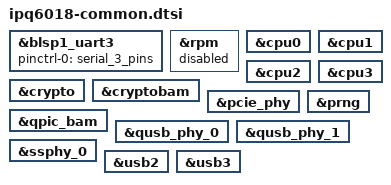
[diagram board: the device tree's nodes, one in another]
// SPDX-License-Identifier: GPL-2.0-or-later OR MIT

&blsp1_uart3 {
	status = "okay";
	pinctrl-0 = <&serial_3_pins>;
	pinctrl-names = "default";
};

&rpm {
	status = "disabled";
};

&cpu0 {
	/delete-property/ cpu-supply;
};

&cpu1 {
	/delete-property/ cpu-supply;
};

&cpu2 {
	/delete-property/ cpu-supply;
};

&cpu3 {
	/delete-property/ cpu-supply;
};

&crypto {
	status = "okay";
};

&cryptobam {
	status = "okay";
};

&pcie_phy {
	status = "okay";
};

&prng {
	status = "okay";
};

&qpic_bam {
	status = "okay";
};

&qusb_phy_0 {
	status = "okay";
};

&qusb_phy_1 {
	status = "okay";
};

&ssphy_0 {
	status = "okay";
};

&usb2 {
	status = "okay";
};

&usb3 {
	status = "okay";
};
